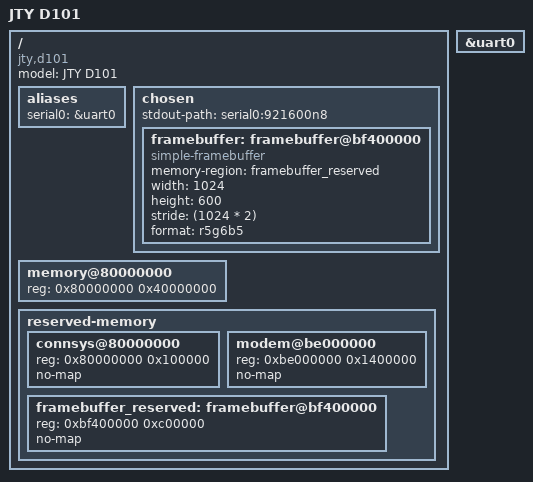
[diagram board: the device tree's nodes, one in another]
// SPDX-License-Identifier: GPL-2.0
/*
 * Copyright (c) 2025 Max Shevchenko <wctrl@proton.me>
 */

/dts-v1/;
#include "mt6572.dtsi"

/ {
	model = "JTY D101";
	compatible = "jty,d101", "mediatek,mt6572";

	aliases {
		serial0 = &uart0;
	};

	chosen {
		#address-cells = <1>;
		#size-cells = <1>;
		stdout-path = "serial0:921600n8";

		framebuffer: framebuffer@bf400000 {
			compatible = "simple-framebuffer";
			memory-region = <&framebuffer_reserved>;
			width = <1024>;
			height = <600>;
			stride = <(1024 * 2)>;
			format = "r5g6b5";
		};
	};

	memory@80000000 {
		device_type = "memory";
		reg = <0x80000000 0x40000000>;
	};

	reserved-memory {
		#address-cells = <1>;
		#size-cells = <1>;
		ranges;

		connsys@80000000 {
			reg = <0x80000000 0x100000>;
			no-map;
		};

		modem@be000000 {
			reg = <0xbe000000 0x1400000>;
			no-map;
		};

		framebuffer_reserved: framebuffer@bf400000 {
			reg = <0xbf400000 0xc00000>;
			no-map;
		};
	};
};

&uart0 {
	status = "okay";
};
